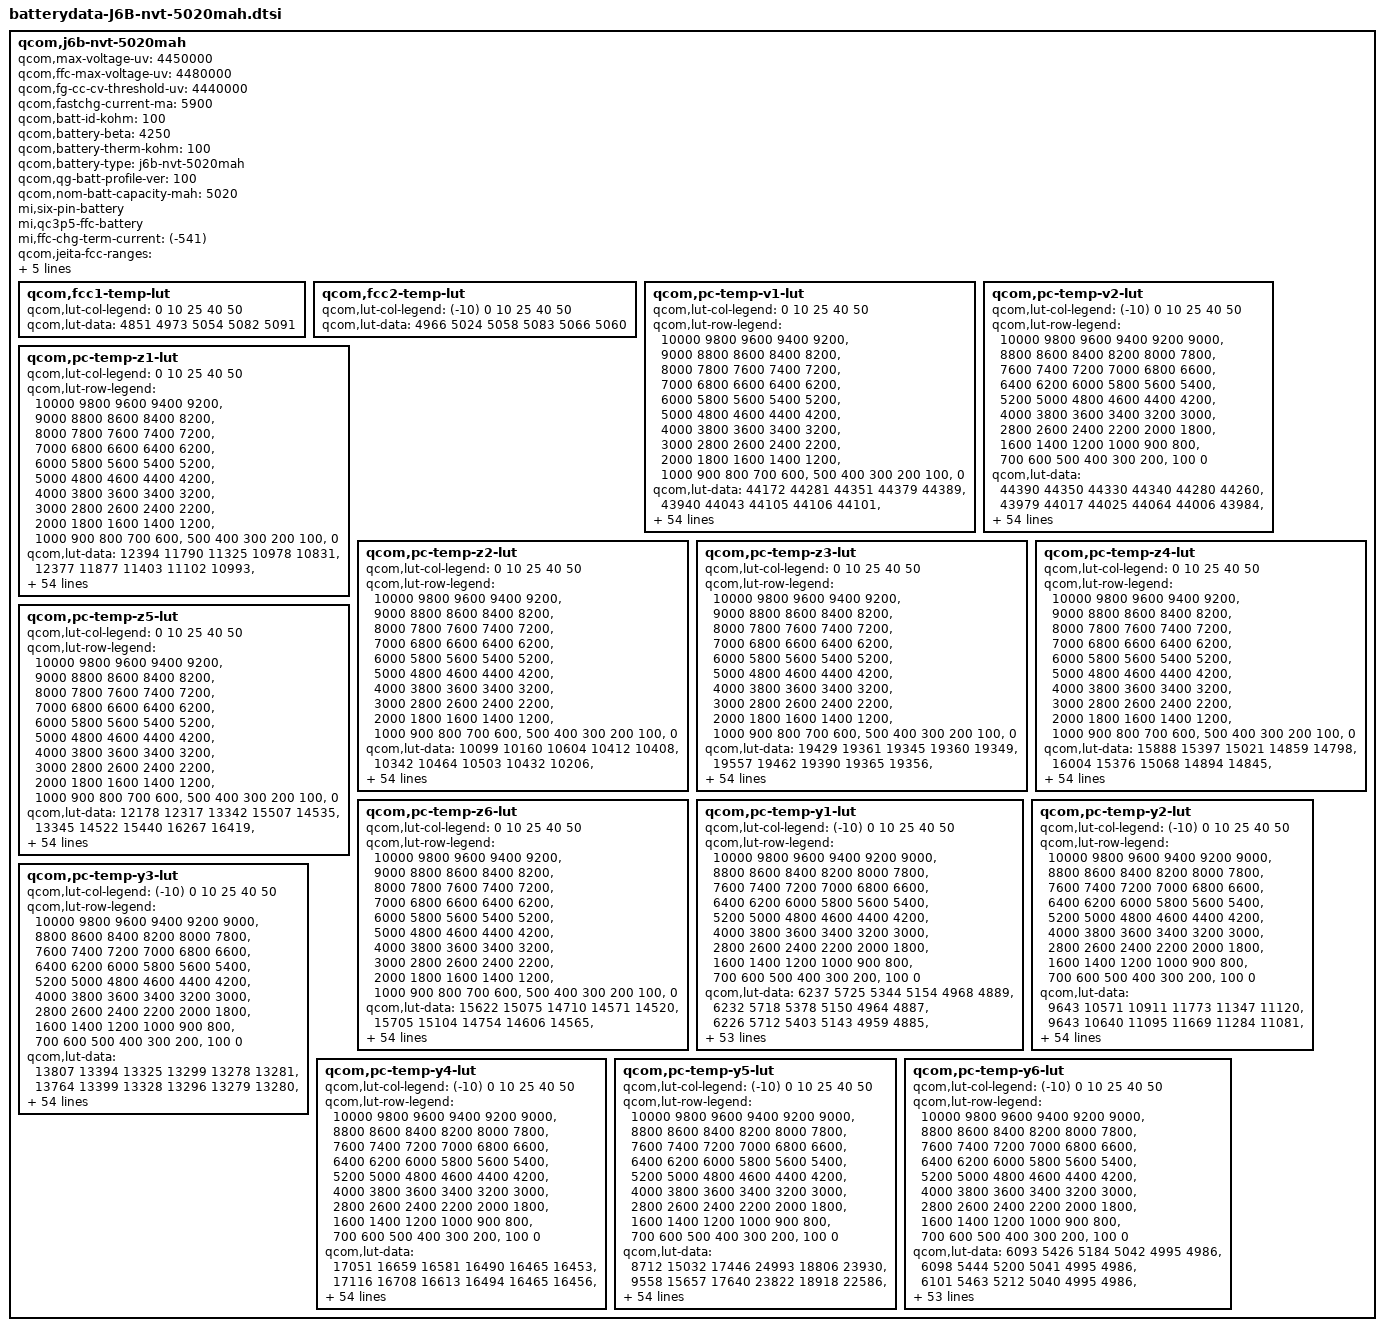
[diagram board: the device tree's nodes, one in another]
/*
 * Copyright (c) 2019, The Linux Foundation. All rights reserved.
 * Copyright (C) 2020 XiaoMi, Inc.
 *
 * This program is free software; you can redistribute it and/or modify
 * it under the terms of the GNU General Public License version 2 and
 * only version 2 as published by the Free Software Foundation.
 *
 * This program is distributed in the hope that it will be useful,
 * but WITHOUT ANY WARRANTY; without even the implied warranty of
 * MERCHANTABILITY or FITNESS FOR A PARTICULAR PURPOSE.  See the
 * GNU General Public License for more details.
 */

qcom,j6b-nvt-5020mah {
    /* 4330536_LC_M524_ATL_5020mAH_PM6250_averaged_MasterSlave_Dec4th2019 */
	qcom,max-voltage-uv = <4450000>;
	qcom,ffc-max-voltage-uv = <4480000>;
	qcom,fg-cc-cv-threshold-uv = <4440000>;
	qcom,fastchg-current-ma = <5900>;
	qcom,batt-id-kohm = <100>;
	qcom,battery-beta = <4250>;
	qcom,battery-therm-kohm = <100>;
	qcom,battery-type = "j6b-nvt-5020mah";
	qcom,qg-batt-profile-ver = <100>;
	qcom,nom-batt-capacity-mah = <5020>;
	mi,six-pin-battery;
	mi,qc3p5-ffc-battery;
	mi,ffc-chg-term-current = <(-541)>;

	qcom,jeita-fcc-ranges = <0  50   900000
				51  100  2300000
				101 150  3300000
				151 450  5900000
				451 580  2300000>;

	qcom,jeita-fv-ranges = <0   50   4450000
				51  100  4450000
				101 150  4450000
				151 450  4480000
				451 580  4100000>;

	qcom,step-chg-ranges = <3001000  4250000  6000000
				4250001  4450000  4900000
				4450001  4480000  3900000>;

	qcom,fcc1-temp-lut {
		qcom,lut-col-legend = <0 10 25 40 50>;
		qcom,lut-data = <4851 4973 5054 5082 5091>;
	};

	qcom,fcc2-temp-lut {
		qcom,lut-col-legend = <(-10) 0 10 25 40 50>;
		qcom,lut-data = <4966 5024 5058 5083 5066 5060>;
	};

	qcom,pc-temp-v1-lut {
		qcom,lut-col-legend = <0 10 25 40 50>;
		qcom,lut-row-legend = <10000 9800 9600 9400 9200>,
			<9000 8800 8600 8400 8200>,
			<8000 7800 7600 7400 7200>,
			<7000 6800 6600 6400 6200>,
			<6000 5800 5600 5400 5200>,
			<5000 4800 4600 4400 4200>,
			<4000 3800 3600 3400 3200>,
			<3000 2800 2600 2400 2200>,
			<2000 1800 1600 1400 1200>,
			<1000 900 800 700 600>,
			<500 400 300 200 100>,
			<0>;
		qcom,lut-data = <44172 44281 44351 44379 44389>,
			<43940 44043 44105 44106 44101>,
			<43707 43810 43876 43878 43869>,
			<43472 43585 43651 43661 43651>,
			<43235 43362 43429 43441 43430>,
			<42995 43131 43206 43222 43212>,
			<42756 42891 42971 42993 42985>,
			<42515 42649 42729 42754 42749>,
			<42274 42407 42485 42513 42509>,
			<42040 42164 42241 42269 42267>,
			<41811 41927 41999 42025 42024>,
			<41588 41693 41763 41786 41785>,
			<41368 41467 41532 41552 41551>,
			<41153 41249 41306 41322 41322>,
			<40945 41037 41084 41099 41102>,
			<40745 40829 40869 40882 40888>,
			<40551 40622 40663 40676 40681>,
			<40357 40424 40466 40479 40478>,
			<40166 40245 40280 40290 40285>,
			<39989 40075 40112 40120 40112>,
			<39837 39904 39938 39947 39941>,
			<39694 39734 39712 39727 39726>,
			<39540 39552 39450 39457 39461>,
			<39373 39311 39238 39232 39238>,
			<39197 39025 39070 39073 39081>,
			<38998 38841 38929 38940 38949>,
			<38789 38749 38812 38815 38822>,
			<38650 38679 38713 38703 38703>,
			<38565 38599 38620 38601 38597>,
			<38499 38520 38530 38508 38502>,
			<38443 38448 38449 38423 38417>,
			<38396 38378 38372 38344 38335>,
			<38352 38317 38302 38271 38257>,
			<38308 38267 38242 38204 38186>,
			<38267 38227 38194 38146 38123>,
			<38231 38187 38149 38089 38060>,
			<38201 38149 38103 38030 37993>,
			<38165 38109 38056 37970 37922>,
			<38112 38050 37992 37895 37837>,
			<38040 37968 37902 37799 37730>,
			<37951 37869 37798 37690 37612>,
			<37828 37749 37682 37577 37496>,
			<37686 37608 37547 37451 37369>,
			<37525 37442 37379 37288 37200>,
			<37352 37279 37220 37140 37061>,
			<37224 37154 37104 37047 36983>,
			<37191 37122 37075 37014 36951>,
			<37150 37093 37050 36995 36932>,
			<37120 37066 37033 36974 36910>,
			<37085 37029 36990 36923 36847>,
			<37011 36855 36783 36676 36576>,
			<36704 36424 36345 36237 36135>,
			<36183 35837 35765 35662 35556>,
			<35481 35022 34970 34869 34764>,
			<34292 33631 33707 33634 33524>,
			<30000 30000 30000 30000 30000>;
	};

	qcom,pc-temp-v2-lut {
		qcom,lut-col-legend = <(-10) 0 10 25 40 50>;
		qcom,lut-row-legend = <10000 9800 9600 9400 9200 9000>,
			<8800 8600 8400 8200 8000 7800>,
			<7600 7400 7200 7000 6800 6600>,
			<6400 6200 6000 5800 5600 5400>,
			<5200 5000 4800 4600 4400 4200>,
			<4000 3800 3600 3400 3200 3000>,
			<2800 2600 2400 2200 2000 1800>,
			<1600 1400 1200 1000 900 800>,
			<700 600 500 400 300 200>,
			<100 0>;
		qcom,lut-data = <44390 44350 44330 44340 44280 44260>,
			<43979 44017 44025 44064 44006 43984>,
			<43621 43717 43746 43803 43748 43724>,
			<43329 43457 43496 43563 43510 43485>,
			<43096 43236 43278 43343 43292 43267>,
			<42867 43014 43055 43120 43071 43047>,
			<42609 42774 42813 42883 42835 42813>,
			<42348 42528 42565 42641 42594 42574>,
			<42117 42278 42318 42398 42353 42333>,
			<41916 42025 42071 42152 42109 42089>,
			<41713 41777 41827 41909 41868 41849>,
			<41480 41535 41586 41669 41630 41611>,
			<41234 41303 41350 41434 41397 41379>,
			<41006 41098 41121 41204 41168 41151>,
			<40807 40920 40900 40981 40945 40929>,
			<40587 40727 40686 40765 40730 40715>,
			<40278 40488 40484 40555 40523 40507>,
			<39907 40226 40285 40353 40325 40306>,
			<39607 39977 40088 40163 40138 40121>,
			<39375 39734 39892 39983 39961 39947>,
			<39166 39498 39679 39780 39768 39758>,
			<38954 39267 39420 39533 39539 39533>,
			<38750 39046 39163 39287 39306 39303>,
			<38588 38854 38962 39077 39098 39097>,
			<38458 38683 38790 38887 38903 38904>,
			<38351 38522 38636 38729 38743 38745>,
			<38269 38351 38496 38598 38615 38618>,
			<38202 38199 38369 38484 38504 38507>,
			<38139 38111 38250 38379 38400 38402>,
			<38080 38054 38139 38283 38304 38304>,
			<38024 38006 38045 38194 38218 38216>,
			<37967 37958 37965 38111 38142 38138>,
			<37911 37913 37900 38034 38070 38064>,
			<37852 37866 37855 37962 37999 37991>,
			<37791 37818 37822 37893 37929 37920>,
			<37726 37767 37784 37821 37846 37831>,
			<37657 37715 37742 37747 37746 37710>,
			<37583 37658 37694 37668 37642 37585>,
			<37501 37589 37629 37585 37545 37485>,
			<37410 37506 37548 37497 37450 37395>,
			<37313 37411 37448 37407 37358 37306>,
			<37214 37299 37321 37314 37270 37220>,
			<37114 37171 37174 37196 37160 37109>,
			<37028 37024 37004 37054 37014 36955>,
			<36955 36883 36853 36921 36893 36837>,
			<36888 36773 36756 36861 36842 36791>,
			<36852 36733 36717 36840 36832 36779>,
			<36804 36696 36675 36821 36818 36764>,
			<36753 36663 36620 36785 36790 36734>,
			<36690 36616 36520 36700 36709 36630>,
			<36601 36518 36273 36408 36394 36295>,
			<36420 36192 35813 35883 35890 35785>,
			<36108 35548 35151 35206 35228 35112>,
			<35493 34610 34146 34245 34285 34171>,
			<34574 33407 32576 32760 32858 32791>,
			<33783 31471 27814 27898 27864 27816>;
	};

	qcom,pc-temp-z1-lut {
		qcom,lut-col-legend = <0 10 25 40 50>;
		qcom,lut-row-legend = <10000 9800 9600 9400 9200>,
			<9000 8800 8600 8400 8200>,
			<8000 7800 7600 7400 7200>,
			<7000 6800 6600 6400 6200>,
			<6000 5800 5600 5400 5200>,
			<5000 4800 4600 4400 4200>,
			<4000 3800 3600 3400 3200>,
			<3000 2800 2600 2400 2200>,
			<2000 1800 1600 1400 1200>,
			<1000 900 800 700 600>,
			<500 400 300 200 100>,
			<0>;
		qcom,lut-data = <12394 11790 11325 10978 10831>,
			<12377 11877 11403 11102 10993>,
			<12409 11921 11418 11120 11010>,
			<12451 11920 11422 11127 11015>,
			<12458 11914 11421 11125 11016>,
			<12457 11906 11420 11120 11015>,
			<12455 11891 11416 11116 11015>,
			<12446 11874 11403 11112 11014>,
			<12429 11862 11392 11109 11014>,
			<12414 11851 11385 11108 11013>,
			<12400 11837 11380 11107 11013>,
			<12386 11815 11378 11106 11013>,
			<12373 11800 11377 11105 11011>,
			<12360 11805 11376 11104 11010>,
			<12352 11816 11376 11104 11011>,
			<12348 11819 11376 11104 11012>,
			<12344 11812 11375 11104 11013>,
			<12338 11806 11375 11104 11014>,
			<12330 11806 11375 11104 11015>,
			<12325 11807 11377 11105 11016>,
			<12330 11809 11380 11107 11018>,
			<12338 11817 11381 11108 11018>,
			<12338 11825 11382 11110 11019>,
			<12329 11829 11383 11111 11019>,
			<12322 11832 11386 11113 11021>,
			<12329 11834 11388 11115 11023>,
			<12348 11836 11390 11117 11026>,
			<12359 11837 11392 11121 11028>,
			<12365 11840 11395 11125 11031>,
			<12369 11844 11401 11127 11033>,
			<12373 11849 11407 11129 11036>,
			<12378 11852 11410 11132 11038>,
			<12382 11856 11413 11136 11041>,
			<12390 11860 11416 11140 11044>,
			<12398 11866 11422 11144 11047>,
			<12403 11872 11428 11148 11050>,
			<12407 11877 11435 11152 11053>,
			<12411 11883 11443 11156 11057>,
			<12427 11893 11448 11159 11059>,
			<12453 11907 11452 11163 11061>,
			<12473 11920 11455 11167 11063>,
			<12486 11928 11463 11170 11066>,
			<12500 11937 11470 11174 11069>,
			<12515 11956 11470 11177 11071>,
			<12532 11963 11480 11180 11073>,
			<12535 11962 11493 11184 11073>,
			<12526 11942 11492 11185 11074>,
			<12496 11964 11497 11186 11074>,
			<12525 11965 11497 11188 11077>,
			<12548 11970 11510 11192 11079>,
			<12572 11960 11516 11198 11085>,
			<12571 11986 11515 11205 11089>,
			<12585 12013 11533 11213 11096>,
			<12572 12042 11550 11226 11108>,
			<12572 12042 11550 11226 11108>,
			<12572 12042 11550 11226 11108>;
	};

	qcom,pc-temp-z2-lut {
		qcom,lut-col-legend = <0 10 25 40 50>;
		qcom,lut-row-legend = <10000 9800 9600 9400 9200>,
			<9000 8800 8600 8400 8200>,
			<8000 7800 7600 7400 7200>,
			<7000 6800 6600 6400 6200>,
			<6000 5800 5600 5400 5200>,
			<5000 4800 4600 4400 4200>,
			<4000 3800 3600 3400 3200>,
			<3000 2800 2600 2400 2200>,
			<2000 1800 1600 1400 1200>,
			<1000 900 800 700 600>,
			<500 400 300 200 100>,
			<0>;
		qcom,lut-data = <10099 10160 10604 10412 10408>,
			<10342 10464 10503 10432 10206>,
			<10361 10615 10636 10456 10298>,
			<10369 10599 10701 10464 10387>,
			<10367 10558 10649 10463 10381>,
			<10349 10517 10581 10457 10351>,
			<10327 10468 10558 10443 10316>,
			<10305 10434 10548 10398 10268>,
			<10284 10425 10538 10366 10235>,
			<10274 10419 10522 10365 10260>,
			<10269 10419 10510 10364 10312>,
			<10267 10422 10511 10364 10323>,
			<10267 10428 10517 10368 10303>,
			<10271 10448 10525 10375 10275>,
			<10276 10486 10541 10405 10240>,
			<10287 10514 10560 10443 10204>,
			<10304 10531 10572 10444 10202>,
			<10324 10546 10581 10421 10227>,
			<10353 10563 10590 10400 10254>,
			<10380 10581 10599 10387 10269>,
			<10400 10597 10611 10378 10285>,
			<10419 10612 10666 10434 10347>,
			<10437 10625 10773 10651 10519>,
			<10457 10640 10803 10757 10609>,
			<10471 10654 10710 10637 10563>,
			<10478 10658 10624 10495 10503>,
			<10481 10634 10640 10511 10499>,
			<10486 10609 10687 10607 10508>,
			<10494 10610 10700 10647 10511>,
			<10501 10623 10674 10581 10425>,
			<10505 10634 10652 10495 10310>,
			<10508 10643 10654 10449 10261>,
			<10512 10650 10661 10415 10228>,
			<10523 10655 10670 10406 10219>,
			<10536 10659 10681 10421 10233>,
			<10542 10665 10695 10446 10258>,
			<10544 10678 10715 10473 10296>,
			<10546 10695 10740 10509 10357>,
			<10560 10711 10758 10556 10416>,
			<10586 10727 10770 10634 10485>,
			<10606 10740 10784 10687 10528>,
			<10620 10749 10819 10672 10518>,
			<10639 10758 10849 10650 10501>,
			<10676 10768 10840 10653 10548>,
			<10951 10895 10874 10660 10550>,
			<11031 10967 10907 10603 10475>,
			<11037 11011 10881 10633 10426>,
			<10999 11058 10883 10574 10469>,
			<10531 11114 10835 10629 10475>,
			<10834 11158 10883 10697 10635>,
			<10500 11203 10950 10574 10461>,
			<10321 11249 10873 10458 10280>,
			<10602 11076 10819 10381 10233>,
			<10423 10766 10724 10329 10137>,
			<10423 10766 10724 10329 10137>,
			<10423 10766 10724 10329 10137>;
	};

	qcom,pc-temp-z3-lut {
		qcom,lut-col-legend = <0 10 25 40 50>;
		qcom,lut-row-legend = <10000 9800 9600 9400 9200>,
			<9000 8800 8600 8400 8200>,
			<8000 7800 7600 7400 7200>,
			<7000 6800 6600 6400 6200>,
			<6000 5800 5600 5400 5200>,
			<5000 4800 4600 4400 4200>,
			<4000 3800 3600 3400 3200>,
			<3000 2800 2600 2400 2200>,
			<2000 1800 1600 1400 1200>,
			<1000 900 800 700 600>,
			<500 400 300 200 100>,
			<0>;
		qcom,lut-data = <19429 19361 19345 19360 19349>,
			<19557 19462 19390 19365 19356>,
			<19637 19521 19419 19381 19373>,
			<19691 19538 19433 19391 19383>,
			<19710 19548 19439 19397 19390>,
			<19720 19550 19442 19401 19394>,
			<19725 19548 19444 19403 19396>,
			<19724 19545 19445 19405 19398>,
			<19721 19543 19445 19405 19399>,
			<19716 19541 19442 19404 19397>,
			<19706 19538 19435 19400 19394>,
			<19694 19535 19428 19397 19391>,
			<19686 19530 19420 19394 19388>,
			<19679 19519 19416 19391 19384>,
			<19672 19505 19415 19389 19380>,
			<19665 19501 19414 19387 19376>,
			<19657 19501 19412 19383 19372>,
			<19647 19501 19409 19378 19370>,
			<19636 19498 19405 19373 19368>,
			<19625 19489 19402 19367 19363>,
			<19614 19486 19399 19362 19359>,
			<19605 19488 19405 19365 19359>,
			<19604 19491 19421 19379 19365>,
			<19612 19496 19425 19385 19368>,
			<19621 19503 19411 19373 19365>,
			<19626 19506 19398 19359 19360>,
			<19631 19499 19400 19366 19367>,
			<19632 19491 19407 19393 19393>,
			<19628 19491 19413 19405 19405>,
			<19623 19493 19419 19401 19399>,
			<19618 19495 19423 19396 19390>,
			<19613 19498 19423 19391 19383>,
			<19609 19501 19422 19386 19378>,
			<19606 19500 19421 19381 19371>,
			<19604 19495 19415 19375 19362>,
			<19601 19491 19409 19369 19354>,
			<19596 19489 19404 19363 19349>,
			<19591 19487 19400 19358 19344>,
			<19585 19484 19398 19357 19343>,
			<19579 19478 19396 19359 19345>,
			<19572 19473 19394 19360 19348>,
			<19564 19469 19391 19360 19350>,
			<19554 19464 19388 19360 19353>,
			<19539 19455 19384 19360 19357>,
			<19490 19427 19375 19358 19356>,
			<19429 19415 19371 19346 19343>,
			<19319 19398 19362 19344 19342>,
			<19306 19392 19361 19337 19331>,
			<19266 19381 19347 19332 19323>,
			<19287 19369 19344 19327 19322>,
			<19262 19370 19346 19342 19338>,
			<19275 19316 19345 19356 19349>,
			<19309 19326 19349 19351 19353>,
			<19330 19336 19349 19354 19347>,
			<19330 19336 19349 19354 19347>,
			<19330 19336 19349 19354 19347>;
	};

	qcom,pc-temp-z4-lut {
		qcom,lut-col-legend = <0 10 25 40 50>;
		qcom,lut-row-legend = <10000 9800 9600 9400 9200>,
			<9000 8800 8600 8400 8200>,
			<8000 7800 7600 7400 7200>,
			<7000 6800 6600 6400 6200>,
			<6000 5800 5600 5400 5200>,
			<5000 4800 4600 4400 4200>,
			<4000 3800 3600 3400 3200>,
			<3000 2800 2600 2400 2200>,
			<2000 1800 1600 1400 1200>,
			<1000 900 800 700 600>,
			<500 400 300 200 100>,
			<0>;
		qcom,lut-data = <15888 15397 15021 14859 14798>,
			<16004 15376 15068 14894 14845>,
			<15861 15327 15005 14865 14827>,
			<15624 15233 14942 14828 14801>,
			<15451 15098 14893 14802 14781>,
			<15303 15006 14849 14778 14762>,
			<15183 14945 14815 14758 14744>,
			<15093 14896 14786 14739 14728>,
			<15021 14855 14763 14725 14715>,
			<14965 14821 14742 14714 14707>,
			<14920 14792 14727 14705 14701>,
			<14883 14767 14722 14699 14698>,
			<14852 14749 14720 14695 14695>,
			<14826 14743 14717 14691 14693>,
			<14803 14740 14709 14686 14690>,
			<14781 14735 14702 14681 14687>,
			<14765 14730 14698 14677 14683>,
			<14763 14725 14696 14675 14679>,
			<14765 14720 14693 14673 14675>,
			<14765 14716 14689 14669 14669>,
			<14758 14714 14687 14666 14664>,
			<14746 14715 14701 14677 14675>,
			<14741 14715 14741 14723 14730>,
			<14739 14742 14773 14758 14760>,
			<14738 14816 14798 14775 14760>,
			<14761 14847 14813 14786 14760>,
			<14814 14833 14804 14774 14750>,
			<14833 14811 14779 14731 14710>,
			<14827 14794 14758 14705 14687>,
			<14818 14778 14739 14698 14683>,
			<14808 14765 14725 14693 14681>,
			<14795 14754 14718 14688 14678>,
			<14783 14745 14714 14684 14675>,
			<14772 14740 14711 14682 14672>,
			<14763 14736 14708 14680 14669>,
			<14753 14732 14707 14679 14667>,
			<14744 14728 14706 14679 14668>,
			<14735 14724 14705 14681 14669>,
			<14726 14722 14705 14683 14672>,
			<14717 14720 14707 14690 14682>,
			<14711 14717 14708 14695 14691>,
			<14707 14708 14701 14690 14685>,
			<14702 14697 14689 14682 14677>,
			<14693 14690 14684 14681 14681>,
			<14676 14675 14669 14672 14675>,
			<14719 14662 14653 14659 14655>,
			<14840 14671 14652 14654 14650>,
			<14849 14667 14642 14648 14645>,
			<14888 14674 14643 14634 14633>,
			<14863 14682 14641 14629 14623>,
			<14882 14687 14651 14645 14650>,
			<14886 14761 14664 14647 14655>,
			<14867 14758 14662 14654 14656>,
			<14867 14760 14667 14653 14664>,
			<14867 14760 14667 14653 14664>,
			<14867 14760 14667 14653 14664>;
	};

	qcom,pc-temp-z5-lut {
		qcom,lut-col-legend = <0 10 25 40 50>;
		qcom,lut-row-legend = <10000 9800 9600 9400 9200>,
			<9000 8800 8600 8400 8200>,
			<8000 7800 7600 7400 7200>,
			<7000 6800 6600 6400 6200>,
			<6000 5800 5600 5400 5200>,
			<5000 4800 4600 4400 4200>,
			<4000 3800 3600 3400 3200>,
			<3000 2800 2600 2400 2200>,
			<2000 1800 1600 1400 1200>,
			<1000 900 800 700 600>,
			<500 400 300 200 100>,
			<0>;
		qcom,lut-data = <12178 12317 13342 15507 14535>,
			<13345 14522 15440 16267 16419>,
			<14308 16102 17314 18003 18827>,
			<15149 16985 18487 19361 20888>,
			<15856 17616 19022 20159 22310>,
			<16436 18183 19454 20755 23429>,
			<17043 18647 20119 21430 24546>,
			<17800 19179 20976 22173 25660>,
			<18619 20012 21842 22979 26777>,
			<19345 21121 22886 23964 28057>,
			<19940 22394 23651 24995 29328>,
			<20589 24198 23500 25721 30070>,
			<21480 25406 22874 26203 30572>,
			<22607 25267 22665 26781 30802>,
			<23876 24866 23906 28051 30662>,
			<25724 24933 25532 29367 30419>,
			<27247 27412 26340 29495 30683>,
			<27350 29760 26900 29112 32661>,
			<27040 29435 27491 28816 34729>,
			<26853 28321 28015 28695 36223>,
			<26923 28171 28788 28622 37443>,
			<27125 32843 33418 30365 38034>,
			<28569 38560 42904 37046 38414>,
			<37035 41273 45276 40171 38462>,
			<45832 43222 33926 30831 30750>,
			<50371 43543 23374 19747 20766>,
			<53812 37254 23034 19985 21651>,
			<54531 30445 23302 24394 29234>,
			<50524 29963 23880 27039 32833>,
			<45298 30454 26302 27726 32040>,
			<42313 31301 29600 28280 31139>,
			<39936 34639 33371 29311 31377>,
			<39030 38557 37402 30645 32313>,
			<39723 40006 38694 31390 32603>,
			<40684 40723 38947 31760 30900>,
			<40806 41503 39049 31948 29069>,
			<40491 42803 38882 31713 28699>,
			<40264 43892 38419 31150 28521>,
			<40931 43764 37850 31043 28562>,
			<42200 42570 37026 31797 29512>,
			<42417 41222 36057 32440 30420>,
			<40519 40121 34960 31373 30546>,
			<38314 38621 33811 29802 30630>,
			<36174 35312 32615 30645 34226>,
			<35439 32241 32713 31850 35669>,
			<25481 32580 35630 26513 27919>,
			<12965 23836 29062 25804 26064>,
			<12625 22811 30726 23511 22204>,
			<11828 19850 23602 25941 24236>,
			<12083 18214 23570 26339 29794>,
			<11765 18056 21938 28106 28288>,
			<11930 13430 19209 27832 24780>,
			<12397 13562 19301 21907 22859>,
			<12956 13900 18255 20759 18176>,
			<12956 13900 18255 20759 18176>,
			<12956 13900 18255 20759 18176>;
	};

	qcom,pc-temp-z6-lut {
		qcom,lut-col-legend = <0 10 25 40 50>;
		qcom,lut-row-legend = <10000 9800 9600 9400 9200>,
			<9000 8800 8600 8400 8200>,
			<8000 7800 7600 7400 7200>,
			<7000 6800 6600 6400 6200>,
			<6000 5800 5600 5400 5200>,
			<5000 4800 4600 4400 4200>,
			<4000 3800 3600 3400 3200>,
			<3000 2800 2600 2400 2200>,
			<2000 1800 1600 1400 1200>,
			<1000 900 800 700 600>,
			<500 400 300 200 100>,
			<0>;
		qcom,lut-data = <15622 15075 14710 14571 14520>,
			<15705 15104 14754 14606 14565>,
			<15651 15110 14746 14603 14565>,
			<15557 15078 14735 14599 14565>,
			<15477 15007 14715 14592 14563>,
			<15398 14955 14692 14582 14556>,
			<15328 14918 14676 14574 14550>,
			<15273 14886 14662 14568 14544>,
			<15226 14859 14649 14561 14539>,
			<15185 14837 14637 14555 14534>,
			<15150 14817 14626 14549 14530>,
			<15119 14800 14619 14544 14526>,
			<15093 14786 14613 14541 14524>,
			<15071 14776 14609 14537 14521>,
			<15052 14768 14605 14534 14517>,
			<15032 14762 14602 14530 14512>,
			<15017 14759 14598 14527 14509>,
			<15008 14756 14595 14523 14506>,
			<15003 14751 14593 14519 14503>,
			<14997 14745 14589 14514 14498>,
			<14989 14744 14587 14511 14493>,
			<14982 14745 14597 14518 14499>,
			<14981 14748 14624 14547 14525>,
			<14985 14765 14637 14561 14540>,
			<14993 14802 14641 14562 14539>,
			<15010 14817 14643 14562 14538>,
			<15035 14808 14641 14561 14536>,
			<15044 14797 14636 14558 14534>,
			<15041 14791 14631 14554 14531>,
			<15037 14787 14626 14549 14527>,
			<15032 14784 14623 14545 14521>,
			<15026 14783 14621 14541 14517>,
			<15021 14781 14619 14537 14513>,
			<15018 14779 14617 14533 14509>,
			<15015 14776 14614 14529 14503>,
			<15013 14775 14612 14526 14498>,
			<15011 14775 14610 14524 14496>,
			<15010 14775 14609 14522 14494>,
			<15010 14775 14608 14522 14494>,
			<15012 14775 14610 14526 14500>,
			<15013 14776 14610 14530 14505>,
			<15016 14774 14607 14528 14504>,
			<15017 14772 14603 14525 14502>,
			<15017 14770 14600 14525 14505>,
			<15001 14758 14592 14521 14503>,
			<14993 14750 14585 14509 14488>,
			<14989 14746 14580 14506 14485>,
			<14988 14743 14576 14500 14478>,
			<14986 14741 14570 14491 14469>,
			<14988 14742 14570 14487 14464>,
			<14994 14749 14578 14503 14484>,
			<15008 14759 14586 14513 14495>,
			<15025 14771 14591 14516 14500>,
			<15050 14788 14597 14520 14503>,
			<15050 14788 14597 14520 14503>,
			<15050 14788 14597 14520 14503>;
	};

	qcom,pc-temp-y1-lut {
		qcom,lut-col-legend = <(-10) 0 10 25 40 50>;
		qcom,lut-row-legend = <10000 9800 9600 9400 9200 9000>,
			<8800 8600 8400 8200 8000 7800>,
			<7600 7400 7200 7000 6800 6600>,
			<6400 6200 6000 5800 5600 5400>,
			<5200 5000 4800 4600 4400 4200>,
			<4000 3800 3600 3400 3200 3000>,
			<2800 2600 2400 2200 2000 1800>,
			<1600 1400 1200 1000 900 800>,
			<700 600 500 400 300 200>,
			<100 0>;
		qcom,lut-data = <6237 5725 5344 5154 4968 4889>,
			<6232 5718 5378 5150 4964 4887>,
			<6226 5712 5403 5143 4959 4885>,
			<6219 5708 5420 5135 4955 4883>,
			<6214 5705 5430 5128 4951 4881>,
			<6211 5704 5433 5125 4949 4880>,
			<6209 5706 5424 5125 4948 4880>,
			<6208 5709 5411 5125 4948 4879>,
			<6208 5709 5409 5124 4946 4879>,
			<6209 5709 5409 5119 4943 4878>,
			<6210 5709 5410 5115 4941 4878>,
			<6214 5713 5410 5114 4940 4877>,
			<6221 5722 5411 5113 4939 4877>,
			<6226 5727 5411 5112 4939 4877>,
			<6231 5731 5409 5112 4938 4877>,
			<6233 5733 5408 5112 4938 4877>,
			<6227 5730 5410 5110 4939 4878>,
			<6210 5725 5411 5108 4940 4878>,
			<6202 5724 5409 5108 4940 4879>,
			<6198 5724 5402 5109 4940 4881>,
			<6196 5725 5399 5111 4941 4881>,
			<6205 5725 5403 5112 4943 4880>,
			<6228 5725 5409 5114 4945 4879>,
			<6236 5722 5414 5118 4945 4879>,
			<6235 5708 5420 5122 4945 4882>,
			<6233 5699 5421 5124 4945 4884>,
			<6217 5709 5419 5125 4947 4884>,
			<6181 5722 5417 5126 4948 4884>,
			<6168 5725 5419 5128 4949 4885>,
			<6196 5725 5428 5131 4951 4889>,
			<6227 5726 5432 5134 4952 4891>,
			<6225 5733 5434 5140 4954 4892>,
			<6208 5743 5435 5144 4956 4892>,
			<6193 5745 5435 5144 4959 4894>,
			<6177 5743 5435 5144 4963 4896>,
			<6165 5740 5435 5145 4965 4897>,
			<6171 5736 5445 5147 4965 4897>,
			<6195 5732 5455 5149 4965 4898>,
			<6208 5732 5455 5152 4966 4900>,
			<6209 5734 5454 5156 4966 4906>,
			<6210 5737 5453 5159 4967 4907>,
			<6210 5739 5455 5163 4969 4902>,
			<6211 5741 5458 5163 4971 4900>,
			<6213 5746 5462 5163 4974 4904>,
			<6215 5753 5465 5176 4980 4902>,
			<6231 5784 5483 5183 4980 4908>,
			<6259 5772 5473 5178 4979 4905>,
			<6287 5753 5475 5184 4977 4907>,
			<6272 5799 5495 5190 4979 4907>,
			<6297 5797 5477 5184 4975 4908>,
			<6353 5813 5500 5183 4980 4910>,
			<6396 5881 5532 5202 4983 4914>,
			<6581 6025 5584 5213 4987 4916>,
			<6806 6207 5681 5231 4995 4922>,
			<6806 6207 5681 5231 4995 4922>,
			<6806 6207 5681 5231 4995 4922>;
	};

	qcom,pc-temp-y2-lut {
		qcom,lut-col-legend = <(-10) 0 10 25 40 50>;
		qcom,lut-row-legend = <10000 9800 9600 9400 9200 9000>,
			<8800 8600 8400 8200 8000 7800>,
			<7600 7400 7200 7000 6800 6600>,
			<6400 6200 6000 5800 5600 5400>,
			<5200 5000 4800 4600 4400 4200>,
			<4000 3800 3600 3400 3200 3000>,
			<2800 2600 2400 2200 2000 1800>,
			<1600 1400 1200 1000 900 800>,
			<700 600 500 400 300 200>,
			<100 0>;
		qcom,lut-data = <9643 10571 10911 11773 11347 11120>,
			<9643 10640 11095 11669 11284 11081>,
			<9643 10728 11208 11542 11205 11043>,
			<9874 10815 11268 11415 11125 11009>,
			<10183 10881 11291 11310 11059 10977>,
			<10347 10907 11295 11251 11023 10949>,
			<10380 10897 11248 11227 11006 10926>,
			<10400 10879 11174 11211 10996 10905>,
			<10462 10870 11143 11186 10996 10885>,
			<10659 10863 11127 11154 11003 10865>,
			<10800 10860 11118 11140 11010 10849>,
			<10771 10939 11113 11145 11020 10837>,
			<10678 11058 11110 11155 11029 10828>,
			<10518 11065 11119 11165 11012 10830>,
			<10094 10989 11161 11179 10942 10840>,
			<9754 10942 11214 11196 10908 10846>,
			<9710 11061 11282 11218 10927 10847>,
			<9690 11240 11360 11249 10962 10849>,
			<9683 11267 11438 11318 11002 10857>,
			<9681 11243 11522 11431 11056 10888>,
			<9680 11220 11552 11469 11121 10931>,
			<9678 11209 11507 11438 11226 11027>,
			<9675 11199 11445 11407 11309 11114>,
			<9674 11171 11415 11418 11284 11120>,
			<9672 11099 11394 11454 11194 11112>,
			<9671 11040 11387 11488 11160 11110>,
			<9670 11019 11388 11518 11209 11147>,
			<9669 11000 11390 11548 11276 11192>,
			<9668 10854 11389 11580 11322 11206>,
			<9667 10296 11386 11612 11363 11212>,
			<9667 9895 11381 11633 11402 11225>,
			<9666 9797 11374 11650 11442 11284>,
			<9665 9738 11361 11659 11478 11343>,
			<9664 9713 11333 11654 11513 11363>,
			<9664 9699 11275 11641 11544 11375>,
			<9664 9689 11209 11629 11542 11373>,
			<9664 9680 11134 11619 11448 11308>,
			<9663 9674 11044 11602 11367 11238>,
			<9663 9670 10940 11529 11370 11216>,
			<9663 9667 10810 11432 11382 11203>,
			<9662 9665 10606 11416 11384 11205>,
			<9662 9663 10196 11429 11371 11250>,
			<9662 9661 9909 11391 11345 11249>,
			<9661 9661 9765 11292 11287 11111>,
			<9660 9660 9707 11347 11228 11051>,
			<9659 9659 9687 11276 11108 10956>,
			<9658 9658 9677 11219 11139 10920>,
			<9657 9658 9670 11204 11077 10865>,
			<9656 9657 9665 11156 11142 10833>,
			<9654 9656 9661 11195 11136 10930>,
			<9650 9654 9658 11125 11040 10911>,
			<9650 9650 9656 11020 11004 10768>,
			<9649 9649 9653 10879 10907 10715>,
			<9649 9649 9653 10727 10738 10574>,
			<9649 9649 9653 10727 10738 10574>,
			<9649 9649 9653 10727 10738 10574>;
	};

	qcom,pc-temp-y3-lut {
		qcom,lut-col-legend = <(-10) 0 10 25 40 50>;
		qcom,lut-row-legend = <10000 9800 9600 9400 9200 9000>,
			<8800 8600 8400 8200 8000 7800>,
			<7600 7400 7200 7000 6800 6600>,
			<6400 6200 6000 5800 5600 5400>,
			<5200 5000 4800 4600 4400 4200>,
			<4000 3800 3600 3400 3200 3000>,
			<2800 2600 2400 2200 2000 1800>,
			<1600 1400 1200 1000 900 800>,
			<700 600 500 400 300 200>,
			<100 0>;
		qcom,lut-data = <13807 13394 13325 13299 13278 13281>,
			<13764 13399 13328 13296 13279 13280>,
			<13722 13404 13332 13294 13280 13280>,
			<13682 13409 13336 13293 13281 13280>,
			<13648 13413 13339 13293 13282 13280>,
			<13620 13416 13341 13292 13283 13281>,
			<13597 13418 13342 13293 13284 13282>,
			<13579 13420 13342 13294 13284 13283>,
			<13575 13420 13343 13295 13285 13283>,
			<13574 13418 13345 13295 13286 13283>,
			<13574 13416 13346 13296 13286 13283>,
			<13543 13424 13347 13296 13287 13284>,
			<13484 13436 13348 13296 13287 13285>,
			<13472 13431 13347 13298 13287 13285>,
			<13507 13396 13345 13300 13287 13285>,
			<13537 13373 13342 13302 13286 13286>,
			<13532 13379 13340 13303 13289 13285>,
			<13518 13388 13338 13303 13292 13285>,
			<13505 13387 13336 13303 13292 13286>,
			<13491 13376 13335 13302 13292 13288>,
			<13482 13365 13332 13301 13292 13289>,
			<13480 13357 13326 13299 13291 13287>,
			<13479 13351 13319 13296 13288 13285>,
			<13479 13346 13316 13293 13285 13282>,
			<13482 13343 13315 13291 13281 13279>,
			<13488 13339 13313 13289 13280 13278>,
			<13500 13328 13311 13288 13280 13279>,
			<13524 13316 13309 13288 13280 13279>,
			<13551 13315 13308 13288 13279 13279>,
			<13579 13323 13307 13288 13279 13278>,
			<13611 13332 13305 13288 13279 13278>,
			<13647 13342 13303 13288 13279 13278>,
			<13689 13353 13301 13288 13280 13277>,
			<13732 13367 13302 13287 13280 13278>,
			<13776 13385 13306 13287 13280 13279>,
			<13820 13407 13310 13287 13280 13279>,
			<13864 13435 13314 13287 13280 13277>,
			<13909 13471 13318 13287 13280 13275>,
			<13952 13519 13322 13286 13279 13276>,
			<13993 13587 13327 13285 13279 13277>,
			<14032 13661 13333 13285 13280 13279>,
			<14067 13740 13341 13287 13282 13281>,
			<14098 13822 13354 13288 13282 13281>,
			<14145 13904 13376 13288 13280 13278>,
			<14217 13993 13409 13289 13278 13277>,
			<14326 14028 13434 13292 13282 13282>,
			<14374 14110 13473 13293 13286 13283>,
			<14510 14201 13538 13298 13288 13286>,
			<14720 14323 13641 13301 13290 13287>,
			<15208 14520 13810 13305 13290 13285>,
			<17025 15073 14048 13303 13286 13282>,
			<21253 17931 14388 13305 13285 13283>,
			<32827 29163 15350 13316 13290 13288>,
			<64924 65535 20878 13332 13295 13297>,
			<64924 65535 20878 13332 13295 13297>,
			<64924 65535 20878 13332 13295 13297>;
	};

	qcom,pc-temp-y4-lut {
		qcom,lut-col-legend = <(-10) 0 10 25 40 50>;
		qcom,lut-row-legend = <10000 9800 9600 9400 9200 9000>,
			<8800 8600 8400 8200 8000 7800>,
			<7600 7400 7200 7000 6800 6600>,
			<6400 6200 6000 5800 5600 5400>,
			<5200 5000 4800 4600 4400 4200>,
			<4000 3800 3600 3400 3200 3000>,
			<2800 2600 2400 2200 2000 1800>,
			<1600 1400 1200 1000 900 800>,
			<700 600 500 400 300 200>,
			<100 0>;
		qcom,lut-data = <17051 16659 16581 16490 16465 16453>,
			<17116 16708 16613 16494 16465 16456>,
			<17178 16789 16654 16497 16464 16458>,
			<17232 16877 16694 16500 16463 16459>,
			<17271 16948 16725 16501 16462 16460>,
			<17286 16977 16737 16502 16461 16460>,
			<17277 16973 16733 16501 16461 16459>,
			<17257 16965 16725 16500 16461 16457>,
			<17238 16959 16717 16500 16461 16457>,
			<17217 16953 16706 16501 16461 16458>,
			<17205 16946 16701 16503 16462 16459>,
			<17252 16930 16702 16507 16464 16459>,
			<17344 16915 16704 16511 16467 16460>,
			<17367 16937 16712 16515 16471 16461>,
			<17330 17063 16735 16519 16477 16464>,
			<17271 17142 16759 16525 16482 16468>,
			<17170 17087 16784 16538 16486 16472>,
			<17025 16986 16803 16556 16490 16478>,
			<16932 16922 16804 16584 16503 16488>,
			<16882 16876 16798 16621 16529 16503>,
			<16840 16832 16786 16633 16539 16509>,
			<16786 16783 16725 16600 16532 16506>,
			<16732 16734 16649 16557 16519 16501>,
			<16710 16693 16613 16523 16500 16490>,
			<16705 16658 16590 16493 16473 16469>,
			<16702 16625 16572 16484 16463 16458>,
			<16704 16587 16559 16483 16463 16457>,
			<16711 16555 16547 16482 16463 16456>,
			<16718 16553 16531 16484 16464 16457>,
			<16724 16564 16513 16489 16469 16462>,
			<16731 16579 16503 16493 16475 16468>,
			<16736 16596 16497 16497 16483 16475>,
			<16742 16615 16494 16500 16491 16484>,
			<16747 16632 16499 16501 16497 16492>,
			<16752 16646 16515 16501 16503 16501>,
			<16757 16662 16533 16499 16503 16502>,
			<16763 16682 16555 16487 16490 16487>,
			<16769 16700 16576 16476 16476 16471>,
			<16772 16703 16593 16472 16469 16468>,
			<16765 16703 16608 16469 16464 16466>,
			<16755 16703 16619 16471 16464 16467>,
			<16754 16699 16627 16483 16473 16485>,
			<16755 16691 16632 16490 16474 16489>,
			<16759 16678 16634 16493 16459 16463>,
			<16768 16664 16638 16486 16445 16442>,
			<16780 16642 16625 16483 16454 16460>,
			<16756 16651 16642 16500 16475 16493>,
			<16772 16664 16670 16520 16509 16529>,
			<16787 16678 16715 16553 16544 16565>,
			<16819 16703 16774 16581 16559 16559>,
			<17095 16741 16819 16558 16483 16485>,
			<17947 17060 16831 16542 16472 16473>,
			<22179 19473 16979 16573 16474 16470>,
			<56568 45822 20081 16623 16485 16484>,
			<56568 45822 20081 16623 16485 16484>,
			<56568 45822 20081 16623 16485 16484>;
	};

	qcom,pc-temp-y5-lut {
		qcom,lut-col-legend = <(-10) 0 10 25 40 50>;
		qcom,lut-row-legend = <10000 9800 9600 9400 9200 9000>,
			<8800 8600 8400 8200 8000 7800>,
			<7600 7400 7200 7000 6800 6600>,
			<6400 6200 6000 5800 5600 5400>,
			<5200 5000 4800 4600 4400 4200>,
			<4000 3800 3600 3400 3200 3000>,
			<2800 2600 2400 2200 2000 1800>,
			<1600 1400 1200 1000 900 800>,
			<700 600 500 400 300 200>,
			<100 0>;
		qcom,lut-data = <8712 15032 17446 24993 18806 23930>,
			<9558 15657 17640 23822 18918 22586>,
			<11953 16255 18038 22075 18966 21725>,
			<14511 16809 18497 20209 18966 21241>,
			<16661 17302 18872 18679 18931 21028>,
			<17829 17715 19020 17940 18878 20984>,
			<18097 18113 19015 17776 18749 21365>,
			<18257 18419 19000 17664 18582 21903>,
			<18822 18398 18982 17442 18493 21728>,
			<20785 18052 18949 17087 18447 20549>,
			<22210 17833 18891 16702 18363 19639>,
			<20888 18215 18563 16203 17918 19340>,
			<18281 18794 17968 15807 17214 19102>,
			<17951 18696 17153 15851 16520 18702>,
			<21535 17674 15939 16115 15734 18124>,
			<24573 17035 15405 16219 15422 17476>,
			<22817 18833 16108 15837 15808 16579>,
			<18794 21607 17436 15424 16271 15825>,
			<17457 22290 19119 15496 16133 15717>,
			<17438 22399 21453 15921 15527 15697>,
			<17418 22521 22677 16709 15365 15751>,
			<17002 22730 22922 19667 18379 17936>,
			<15876 23019 23111 22273 21671 20446>,
			<14830 23524 23604 22373 21565 20475>,
			<13780 24463 24400 22289 20439 19836>,
			<13021 24970 24706 22157 19680 19573>,
			<12856 21055 24533 21816 19372 19866>,
			<12776 15320 24348 21557 19090 20177>,
			<12757 14284 24396 21795 18541 19679>,
			<12824 14266 24574 22362 17835 18175>,
			<12948 14238 24497 22687 17638 17369>,
			<13125 14056 21811 22820 18050 17113>,
			<13405 13826 19104 22984 18692 16987>,
			<13682 13813 19110 23422 19378 17766>,
			<13966 13959 19540 24084 20224 19742>,
			<14208 14153 19689 24632 21174 20392>,
			<14332 14393 19574 25163 22478 19778>,
			<14419 14684 19404 25430 23319 19208>,
			<14450 14992 19267 23577 23148 19881>,
			<14430 15352 19117 20577 22753 21695>,
			<14379 15521 18834 19962 22766 22995>,
			<14098 15367 18074 19942 23646 23899>,
			<13296 15075 17038 19568 23835 24092>,
			<13036 14624 15669 18749 22906 23517>,
			<12979 14338 14749 19442 19880 20377>,
			<13213 13966 14839 20715 19784 19127>,
			<13504 13789 14537 18772 19548 17098>,
			<13312 13606 14308 18992 17929 16012>,
			<13500 13857 14316 18420 17146 15446>,
			<13483 13942 14664 18834 16671 14828>,
			<12225 14196 14256 18924 18800 16229>,
			<10496 11387 13774 19974 17755 16332>,
			<9371 9531 12408 20236 19656 17209>,
			<8882 8912 9753 20383 21096 25026>,
			<8882 8912 9753 20383 21096 25026>,
			<8882 8912 9753 20383 21096 25026>;
	};

	qcom,pc-temp-y6-lut {
		qcom,lut-col-legend = <(-10) 0 10 25 40 50>;
		qcom,lut-row-legend = <10000 9800 9600 9400 9200 9000>,
			<8800 8600 8400 8200 8000 7800>,
			<7600 7400 7200 7000 6800 6600>,
			<6400 6200 6000 5800 5600 5400>,
			<5200 5000 4800 4600 4400 4200>,
			<4000 3800 3600 3400 3200 3000>,
			<2800 2600 2400 2200 2000 1800>,
			<1600 1400 1200 1000 900 800>,
			<700 600 500 400 300 200>,
			<100 0>;
		qcom,lut-data = <6093 5426 5184 5042 4995 4986>,
			<6098 5444 5200 5041 4995 4986>,
			<6101 5463 5212 5040 4995 4986>,
			<6101 5479 5221 5039 4995 4986>,
			<6099 5491 5227 5038 4995 4987>,
			<6095 5496 5229 5038 4996 4987>,
			<6072 5493 5226 5037 4996 4988>,
			<6032 5488 5220 5037 4996 4988>,
			<6010 5483 5216 5037 4997 4988>,
			<5997 5476 5211 5038 4997 4989>,
			<5988 5472 5209 5038 4998 4989>,
			<5982 5471 5208 5039 4999 4989>,
			<5977 5471 5207 5040 5000 4990>,
			<5972 5473 5208 5042 5001 4991>,
			<5967 5486 5211 5045 5002 4992>,
			<5960 5495 5215 5048 5004 4993>,
			<5930 5485 5220 5052 5006 4995>,
			<5875 5467 5224 5057 5009 4996>,
			<5835 5450 5224 5065 5014 4999>,
			<5808 5433 5221 5075 5021 5005>,
			<5790 5416 5216 5077 5024 5007>,
			<5785 5400 5195 5067 5021 5005>,
			<5782 5385 5170 5052 5015 5002>,
			<5782 5375 5159 5041 5007 4996>,
			<5790 5369 5152 5030 4997 4987>,
			<5804 5363 5147 5027 4993 4984>,
			<5821 5355 5144 5027 4993 4984>,
			<5846 5349 5142 5027 4993 4984>,
			<5873 5351 5139 5028 4993 4985>,
			<5900 5370 5136 5030 4994 4986>,
			<5929 5393 5135 5031 4996 4987>,
			<5960 5417 5136 5033 4999 4989>,
			<5994 5446 5137 5034 5002 4991>,
			<6030 5478 5143 5034 5004 4994>,
			<6067 5517 5156 5035 5006 4998>,
			<6105 5561 5172 5034 5006 4998>,
			<6142 5611 5190 5031 5002 4992>,
			<6178 5667 5211 5029 4998 4987>,
			<6213 5727 5236 5028 4996 4987>,
			<6244 5793 5265 5027 4995 4988>,
			<6274 5862 5297 5028 4995 4989>,
			<6305 5933 5333 5034 4999 4995>,
			<6338 6004 5375 5038 5000 4996>,
			<6383 6075 5423 5041 4994 4987>,
			<6448 6151 5490 5042 4990 4981>,
			<6554 6183 5525 5045 4996 4990>,
			<6595 6252 5589 5051 5005 5001>,
			<6716 6333 5677 5062 5016 5013>,
			<6906 6440 5802 5074 5027 5024>,
			<7346 6616 5980 5085 5031 5021>,
			<8900 7093 6205 5079 5007 4998>,
			<12322 9409 6496 5079 5004 4996>,
			<21725 18040 7328 5106 5009 4999>,
			<53590 64276 12359 5146 5017 5011>,
			<53590 64276 12359 5146 5017 5011>,
			<53590 64276 12359 5146 5017 5011>;
	};

};
